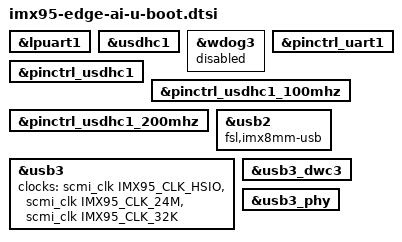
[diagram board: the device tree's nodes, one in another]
// SPDX-License-Identifier: (GPL-2.0+ OR MIT)
/*
 * Copyright 2025 TechNexion Ltd.
 *
 * Author: Ray Chang <ray.chang@technexion.com>
 *
 */

&lpuart1 {
	bootph-pre-ram;
};

&usdhc1 {
	bootph-pre-ram;
};

&wdog3 {
	status = "disabled";
};

&pinctrl_uart1 {
	bootph-pre-ram;
};

&pinctrl_usdhc1 {
	bootph-pre-ram;
};

&pinctrl_usdhc1_100mhz {
	bootph-pre-ram;
};

&pinctrl_usdhc1_200mhz {
	bootph-pre-ram;
};


&usb2 {
	compatible = "fsl,imx8mm-usb", "fsl,imx7d-usb";
	/delete-property/power-domains;
};

&usb3 {
	clocks = <&scmi_clk IMX95_CLK_HSIO>,
		 <&scmi_clk IMX95_CLK_24M>,
		 <&scmi_clk IMX95_CLK_32K>;
	clock-names = "hsio", "ref", "suspend";
	/delete-property/power-domains;
	bootph-pre-ram;
};

&usb3_dwc3 {
	bootph-pre-ram;
};

&usb3_phy {
	bootph-pre-ram;
};
